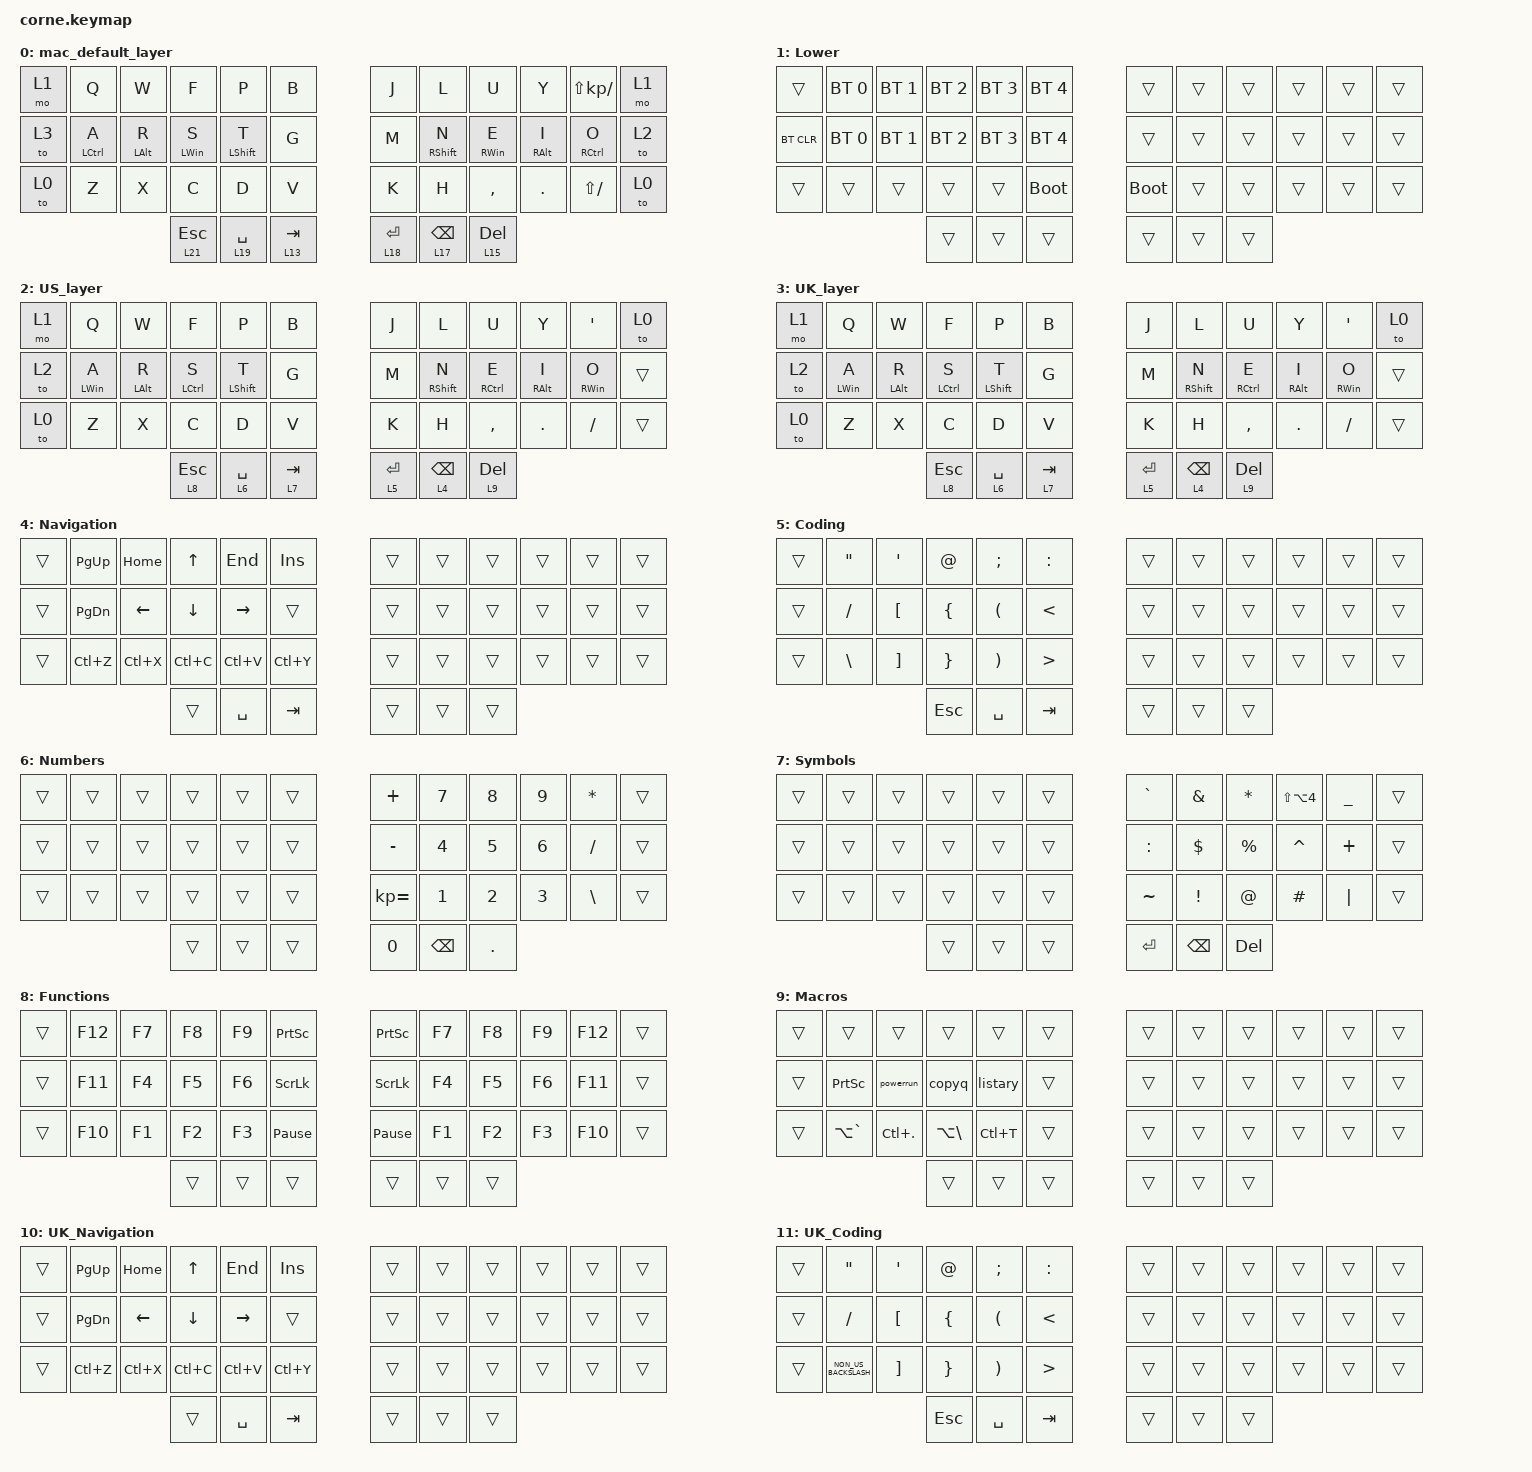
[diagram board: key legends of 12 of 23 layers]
/*
 * Copyright (c) 2020 The ZMK Contributors
 *
 * SPDX-License-Identifier: MIT
 */

#include <behaviors.dtsi>
#include <dt-bindings/zmk/bt.h>
#include <dt-bindings/zmk/keys.h>

/ {
    behaviors {
        htc: htc {
            compatible = "zmk,behavior-hold-tap";
            label = "HTC";
            bindings = <&kp>, <&kp>;

            #binding-cells = <2>;
            tapping-term-ms = <200>;
            hold-trigger-key-positions = <16 15 14 13 19 20 21 22>;
            flavor = "tap-preferred";
        };
    };

    macros {
        copyq: copyq {
            compatible = "zmk,behavior-macro";
            #binding-cells = <0>;
            bindings = <&kt LS(LA(LC(Q)))>;
            label = "COPYQ";
        };

        powerrun: powerrun {
            compatible = "zmk,behavior-macro";
            #binding-cells = <0>;
            bindings = <&kt LS(LA(LC(P)))>;
            label = "POWERRUN";
        };

        listary: listary {
            compatible = "zmk,behavior-macro";
            #binding-cells = <0>;
            bindings = <&kp LS(LA(LC(L)))>;
            label = "LISTARY";
        };

        backslash: backslash {
            compatible = "zmk,behavior-macro";
            #binding-cells = <0>;
            bindings = <&kp RA(BACKSLASH)>;
            label = "BACKSLASH";
        };

        pipe: pipe {
            compatible = "zmk,behavior-macro";
            #binding-cells = <0>;
            bindings = <&kp RA(LS(BACKSLASH))>;
            label = "PIPE";
        };
    };

    keymap {
        compatible = "zmk,keymap";

        mac_default_layer {
            label = "mac_default_layer";
            bindings = <
&mo 1  &kp Q         &kp W        &kp F            &kp P         &kp B         &kp J       &kp L             &kp U             &kp Y        &kp LS(KP_SLASH)  &mo 1
&to 3  &htc LCTRL A  &htc LALT R  &htc LEFT_WIN S  &htc LSHFT T  &kp G         &kp M       &htc RSHFT N      &htc RIGHT_WIN E  &htc RALT I  &htc RCTRL O      &to 2
&to 0  &kp Z         &kp X        &kp C            &kp D         &kp V         &kp K       &kp H             &kp COMMA         &kp DOT      &kp LS(FSLH)      &to 0
                                  &lt 21 ESCAPE    &lt 19 SPACE  &lt 13 TAB    &lt 18 RET  &lt 17 BACKSPACE  &lt 15 DEL
            >;
        };

        lower_layer {
            // -----------------------------------------------------------------------------------------
            // |  TAB |  1  |  2  |  3  |  4  |  5  |   |  6  |  7  |  8  |  9  |  0  | BKSP |
            // | BTCLR| BT1 | BT2 | BT3 | BT4 | BT5 |   | LFT | DWN |  UP | RGT |     |      |
            // | SHFT |     |     |     |     |     |   |     |     |     |     |     |      |
            //                    | GUI |     | SPC |   | ENT |     | ALT |

            label = "Lower";
            bindings = <
&trans      &bt BT_SEL 0  &bt BT_SEL 1  &bt BT_SEL 2  &bt BT_SEL 3  &bt BT_SEL 4    &trans       &trans  &trans  &trans  &trans  &trans
&bt BT_CLR  &bt BT_SEL 0  &bt BT_SEL 1  &bt BT_SEL 2  &bt BT_SEL 3  &bt BT_SEL 4    &trans       &trans  &trans  &trans  &trans  &trans
&trans      &trans        &trans        &trans        &trans        &bootloader     &bootloader  &trans  &trans  &trans  &trans  &trans
                                        &trans        &trans        &trans          &trans       &trans  &trans
            >;
        };

        US_layer {
            // -----------------------------------------------------------------------------------------
            // |  TAB |  Q  |  W  |  E  |  R  |  T  |   |  Y  |  U   |  I  |  O  |  P  | BKSP |
            // | CTRL |  A  |  S  |  D  |  F  |  G  |   |  H  |  J   |  K  |  L  |  ;  |  '   |
            // | SHFT |  Z  |  X  |  C  |  V  |  B  |   |  N  |  M   |  ,  |  .  |  /  | ESC  |
            //                    | GUI | LWR | SPC |   | ENT | RSE  | ALT |

            label = "US_layer";
            bindings = <
&mo 1  &kp Q            &kp W        &kp F         &kp P         &kp B        &kp J      &kp L            &kp U         &kp Y        &kp SINGLE_QUOTE  &to 0
&to 2  &htc LEFT_WIN A  &htc LALT R  &htc LCTRL S  &htc LSHFT T  &kp G        &kp M      &htc RSHFT N     &htc RCTRL E  &htc RALT I  &htc RWIN O       &trans
&to 0  &kp Z            &kp X        &kp C         &kp D         &kp V        &kp K      &kp H            &kp COMMA     &kp DOT      &kp FSLH          &trans
                                     &lt 8 ESCAPE  &lt 6 SPACE   &lt 7 TAB    &lt 5 RET  &lt 4 BACKSPACE  &lt 9 DEL
            >;
        };

        UK_layer {
            // -----------------------------------------------------------------------------------------
            // |  TAB |  Q  |  W  |  E  |  R  |  T  |   |  Y  |  U   |  I  |  O  |  P  | BKSP |
            // | CTRL |  A  |  S  |  D  |  F  |  G  |   |  H  |  J   |  K  |  L  |  ;  |  '   |
            // | SHFT |  Z  |  X  |  C  |  V  |  B  |   |  N  |  M   |  ,  |  .  |  /  | ESC  |
            //                    | GUI | LWR | SPC |   | ENT | RSE  | ALT |

            label = "UK_layer";
            bindings = <
&mo 1  &kp Q            &kp W        &kp F         &kp P         &kp B        &kp J      &kp L            &kp U         &kp Y        &kp SINGLE_QUOTE  &to 0
&to 2  &htc LEFT_WIN A  &htc LALT R  &htc LCTRL S  &htc LSHFT T  &kp G        &kp M      &htc RSHFT N     &htc RCTRL E  &htc RALT I  &htc RWIN O       &trans
&to 0  &kp Z            &kp X        &kp C         &kp D         &kp V        &kp K      &kp H            &kp COMMA     &kp DOT      &kp FSLH          &trans
                                     &lt 8 ESCAPE  &lt 6 SPACE   &lt 7 TAB    &lt 5 RET  &lt 4 BACKSPACE  &lt 9 DEL
            >;
        };

        Nav_Layer {
            bindings = <
&trans  &kp PG_UP      &kp HOME        &kp UP_ARROW    &kp END          &kp INSERT    &trans  &trans  &trans  &trans  &trans  &trans
&trans  &kp PAGE_DOWN  &kp LEFT_ARROW  &kp DOWN_ARROW  &kp RIGHT_ARROW  &trans        &trans  &trans  &trans  &trans  &trans  &trans
&trans  &kp LC(Z)      &kp LC(X)       &kp LC(C)       &kp LC(V)        &kp LC(Y)     &trans  &trans  &trans  &trans  &trans  &trans
                                       &trans          &kp SPACE        &kp TAB       &trans  &trans  &trans
            >;

            label = "Navigation";
        };

        Coding_Layer {
            bindings = <
&trans  &kp DOUBLE_QUOTES  &kp APOSTROPHE     &kp AT           &kp SEMICOLON          &kp COLON           &trans  &trans  &trans  &trans  &trans  &trans
&trans  &kp FSLH           &kp LEFT_BRACKET   &kp LEFT_BRACE   &kp LPAR               &kp LT              &trans  &trans  &trans  &trans  &trans  &trans
&trans  &kp BACKSLASH      &kp RIGHT_BRACKET  &kp RIGHT_BRACE  &kp RIGHT_PARENTHESIS  &kp GREATER_THAN    &trans  &trans  &trans  &trans  &trans  &trans
                                              &kp ESCAPE       &kp SPACE              &kp TAB             &trans  &trans  &trans
            >;

            label = "Coding";
        };

        Num_Layer {
            bindings = <
&trans  &trans  &trans  &trans  &trans  &trans    &kp PLUS      &kp N7         &kp N8      &kp N9  &kp ASTRK  &trans
&trans  &trans  &trans  &trans  &trans  &trans    &kp MINUS     &kp N4         &kp N5      &kp N6  &kp SLASH  &trans
&trans  &trans  &trans  &trans  &trans  &trans    &kp KP_EQUAL  &kp N1         &kp N2      &kp N3  &kp BSLH   &trans
                        &trans  &trans  &trans    &kp N0        &kp BACKSPACE  &kp PERIOD
            >;

            label = "Numbers";
        };

        Symbols_Layer {
            bindings = <
&trans  &trans  &trans  &trans  &trans  &trans    &kp GRAVE  &kp AMPS    &kp STAR     &kp LS(LA(NUMBER_4))  &kp UNDER  &trans
&trans  &trans  &trans  &trans  &trans  &trans    &kp COLON  &kp DOLLAR  &kp PERCENT  &kp CARET             &kp PLUS   &trans
&trans  &trans  &trans  &trans  &trans  &trans    &kp TILDE  &kp EXCL    &kp AT       &kp HASH              &kp PIPE   &trans
                        &trans  &trans  &trans    &kp ENTER  &kp BSPC    &kp DELETE
            >;

            label = "Symbols";
        };

        Functions_Layer {
            bindings = <
&trans  &kp F12  &kp F7  &kp F8  &kp F9  &kp PRINTSCREEN    &kp PRINTSCREEN  &kp F7  &kp F8  &kp F9  &kp F12  &trans
&trans  &kp F11  &kp F4  &kp F5  &kp F6  &kp SCROLLLOCK     &kp SCROLLLOCK   &kp F4  &kp F5  &kp F6  &kp F11  &trans
&trans  &kp F10  &kp F1  &kp F2  &kp F3  &kp PAUSE_BREAK    &kp PAUSE_BREAK  &kp F1  &kp F2  &kp F3  &kp F10  &trans
                         &trans  &trans  &trans             &trans           &trans  &trans
            >;

            label = "Functions";
        };

        Macros {
            bindings = <
&trans  &trans           &trans       &trans        &trans     &trans    &trans  &trans  &trans  &trans  &trans  &trans
&trans  &kp PRINTSCREEN  &powerrun    &copyq        &listary   &trans    &trans  &trans  &trans  &trans  &trans  &trans
&trans  &kp LA(GRAVE)    &kp LC(DOT)  &kp LA(BSLH)  &kp LC(T)  &trans    &trans  &trans  &trans  &trans  &trans  &trans
                                      &trans        &trans     &trans    &trans  &trans  &trans
            >;

            label = "Macros";
        };

        UK_Nav_Layer {
            bindings = <
&trans  &kp PG_UP      &kp HOME        &kp UP_ARROW    &kp END          &kp INSERT    &trans  &trans  &trans  &trans  &trans  &trans
&trans  &kp PAGE_DOWN  &kp LEFT_ARROW  &kp DOWN_ARROW  &kp RIGHT_ARROW  &trans        &trans  &trans  &trans  &trans  &trans  &trans
&trans  &kp LC(Z)      &kp LC(X)       &kp LC(C)       &kp LC(V)        &kp LC(Y)     &trans  &trans  &trans  &trans  &trans  &trans
                                       &trans          &kp SPACE        &kp TAB       &trans  &trans  &trans
            >;

            label = "UK_Navigation";
        };

        UK_Coding_Layer {
            bindings = <
&trans  &kp DOUBLE_QUOTES     &kp APOSTROPHE     &kp AT_SIGN      &kp SEMICOLON          &kp COLON           &trans  &trans  &trans  &trans  &trans  &trans
&trans  &kp FSLH              &kp LEFT_BRACKET   &kp LEFT_BRACE   &kp LPAR               &kp LT              &trans  &trans  &trans  &trans  &trans  &trans
&trans  &kp NON_US_BACKSLASH  &kp RIGHT_BRACKET  &kp RIGHT_BRACE  &kp RIGHT_PARENTHESIS  &kp GREATER_THAN    &trans  &trans  &trans  &trans  &trans  &trans
                                                 &kp ESCAPE       &kp SPACE              &kp TAB             &trans  &trans  &trans
            >;

            label = "UK_Coding";
        };

        UK_Num_Layer {
            bindings = <
&trans  &trans  &trans  &trans  &trans  &trans    &kp PLUS      &kp N7        &kp N8      &kp N9  &kp ASTRK             &trans
&trans  &trans  &trans  &trans  &trans  &trans    &kp MINUS     &kp N4        &kp N5      &kp N6  &kp SLASH             &trans
&trans  &trans  &trans  &trans  &trans  &trans    &kp KP_EQUAL  &kp N1        &kp N2      &kp N3  &kp NON_US_BACKSLASH  &trans
                        &trans  &trans  &trans    &kp N0        &kp NUMBER_0  &kp PERIOD
            >;

            label = "UK_Numbers";
        };

        UK_Symbols_Layer {
            bindings = <
&trans  &trans  &trans  &trans  &trans  &trans    &kp GRAVE  &kp AMPS    &kp STAR           &kp HASH       &kp UNDER  &trans
&trans  &trans  &trans  &trans  &trans  &trans    &kp TILDE  &kp DOLLAR  &kp PERCENT        &kp CARET      &kp PLUS   &trans
&trans  &trans  &trans  &trans  &trans  &trans    &kp PIPE   &kp EXCL    &kp DOUBLE_QUOTES  &kp BACKSLASH  &pipe      &trans
                        &trans  &trans  &trans    &kp ENTER  &kp BSPC    &kp DELETE
            >;

            label = "UK_Symbols";
        };

        UK_Functions_Layer {
            bindings = <
&trans  &kp F12  &kp F7  &kp F8  &kp F9  &kp PRINTSCREEN    &kp PRINTSCREEN  &kp F7  &kp F8  &kp F9  &kp F12  &trans
&trans  &kp F11  &kp F4  &kp F5  &kp F6  &kp SCROLLLOCK     &kp SCROLLLOCK   &kp F4  &kp F5  &kp F6  &kp F11  &trans
&trans  &kp F10  &kp F1  &kp F2  &kp F3  &kp PAUSE_BREAK    &kp PAUSE_BREAK  &kp F1  &kp F2  &kp F3  &kp F10  &trans
                         &trans  &trans  &trans             &trans           &trans  &trans
            >;

            label = "UK_Functions";
        };

        UK_Macros {
            bindings = <
&trans  &kp LS(F5)     &kp F5         &kp F10                   &kp F11                    &kp RS(F11)    &trans  &trans  &trans  &trans  &trans  &trans
&trans  &kp LS(LC(C))  &kp LG(SPACE)  &kp LG(LA(C))             &kp LG(LA(LS(LC(SPACE))))  &trans         &trans  &trans  &trans  &trans  &trans  &trans
&trans  &kp LA(GRAVE)  &kp LC(DOT)    &kp LA(NON_US_BACKSLASH)  &kp LC(T)                  &trans         &trans  &trans  &trans  &trans  &trans  &trans
                                      &trans                    &trans                     &trans         &trans  &trans  &trans
            >;

            label = "UK_Macros";
        };

        UK_Mac_Layer {
            label = "UK_Mac_layer";
            bindings = <
&mo 1  &kp Q         &kp W        &kp F            &kp P         &kp B        &kp J      &kp L            &kp U             &kp Y        &kp SINGLE_QUOTE  &to 0
&to 3  &htc LCTRL A  &htc LALT R  &htc LEFT_WIN S  &htc LSHFT T  &kp G        &kp M      &htc RSHFT N     &htc RIGHT_WIN E  &htc RALT I  &htc RCTRL O      &trans
&to 0  &kp Z         &kp X        &kp C            &kp D         &kp V        &kp K      &kp H            &kp COMMA         &kp DOT      &kp FSLH          &trans
                                  &lt 8 ESCAPE     &lt 6 SPACE   &lt 7 TAB    &lt 5 RET  &lt 4 BACKSPACE  &lt 9 DEL
            >;
        };

        UK_Mac_Navigation {
            label = "UK_Mac_Navigation";
            bindings = <
&trans  &kp PG_UP      &kp HOME        &kp UP_ARROW    &kp END          &kp PG_UP        &trans  &trans  &trans  &trans  &trans  &trans
&trans  &kp PAGE_DOWN  &kp LEFT_ARROW  &kp DOWN_ARROW  &kp RIGHT_ARROW  &kp PAGE_DOWN    &trans  &trans  &trans  &trans  &trans  &trans
&trans  &kp LG(Z)      &kp LG(X)       &kp LG(C)       &kp LG(V)        &kp LG(Y)        &trans  &trans  &trans  &trans  &trans  &trans
                                       &trans          &kp SPACE        &kp TAB          &trans  &trans  &trans
            >;
        };

        UK_Mac_Coding {
            label = "UK_Mac_Coding";
            bindings = <
&trans  &kp AT                &kp APOSTROPHE     &kp DOUBLE_QUOTES  &kp SEMICOLON          &kp COLON           &trans  &trans  &trans  &trans  &trans  &trans
&trans  &kp FSLH              &kp LEFT_BRACKET   &kp LEFT_BRACE     &kp LPAR               &kp LT              &trans  &trans  &trans  &trans  &trans  &trans
&trans  &kp NON_US_BACKSLASH  &kp RIGHT_BRACKET  &kp RIGHT_BRACE    &kp RIGHT_PARENTHESIS  &kp GREATER_THAN    &trans  &trans  &trans  &trans  &trans  &trans
                                                 &trans             &trans                 &trans              &trans  &trans  &trans
            >;
        };

        UK_Mac_Numbers {
            label = "UK_Mac_Numbers";
            bindings = <
&trans  &trans  &trans  &trans  &trans  &trans    &kp PLUS   &kp N7         &kp N8           &kp N9  &kp ASTRK  &trans
&trans  &trans  &trans  &trans  &trans  &trans    &kp MINUS  &kp N4         &kp N5           &kp N6  &kp SLASH  &trans
&trans  &trans  &trans  &trans  &trans  &trans    &kp DOT    &kp N1         &kp N2           &kp N3  &kp EQUAL  &trans
                        &trans  &trans  &trans    &kp ENTER  &kp BACKSPACE  &kp KP_NUMBER_0
            >;
        };

        UK_Mac_Symbols {
            label = "UK_Mac_Symbols";
            bindings = <
&trans  &trans  &trans  &trans  &trans  &trans    &kp GRAVE  &kp AMPS    &kp STAR     &kp HASH          &kp LS(MINUS)  &trans
&trans  &trans  &trans  &trans  &trans  &trans    &kp COLON  &kp DOLLAR  &kp PERCENT  &kp CARET         &kp PLUS       &trans
&trans  &trans  &trans  &trans  &trans  &trans    &kp TILDE  &kp EXCL    &kp AT       &kp RA(NUMBER_3)  &kp PIPE       &trans
                        &trans  &trans  &trans    &kp ENTER  &kp BSPC    &kp DELETE
            >;
        };

        UK_Mac_Functions {
            label = "UK_Mac_Functions";
            bindings = <
&trans  &trans  &trans  &trans  &trans  &trans    &none   &kp F7  &kp F8  &kp F9  &kp F12  &trans
&trans  &trans  &trans  &trans  &trans  &trans    &none   &kp F4  &kp F5  &kp F6  &kp F11  &trans
&trans  &trans  &trans  &trans  &trans  &trans    &none   &kp F1  &kp F2  &kp F3  &kp F10  &trans
                        &trans  &trans  &trans    &trans  &trans  &trans
            >;
        };

        UK_Mac_Macros {
            label = "UK_Mac_Macros";
            bindings = <
&trans  &kp LC(LS(O))  &trans         &trans                    &trans                     &trans    &trans  &trans  &trans  &trans  &trans  &trans
&trans  &kp LS(LC(C))  &kp LG(SPACE)  &kp LA(LG(C))             &kp LS(LA(LC(LG(SPACE))))  &trans    &trans  &trans  &trans  &trans  &trans  &trans
&trans  &kp LA(GRAVE)  &kp LC(DOT)    &kp LA(NON_US_BACKSLASH)  &kp LG(T)                  &trans    &trans  &trans  &trans  &trans  &trans  &trans
                                      &trans                    &trans                     &trans    &trans  &trans  &trans
            >;
        };
    };
};
